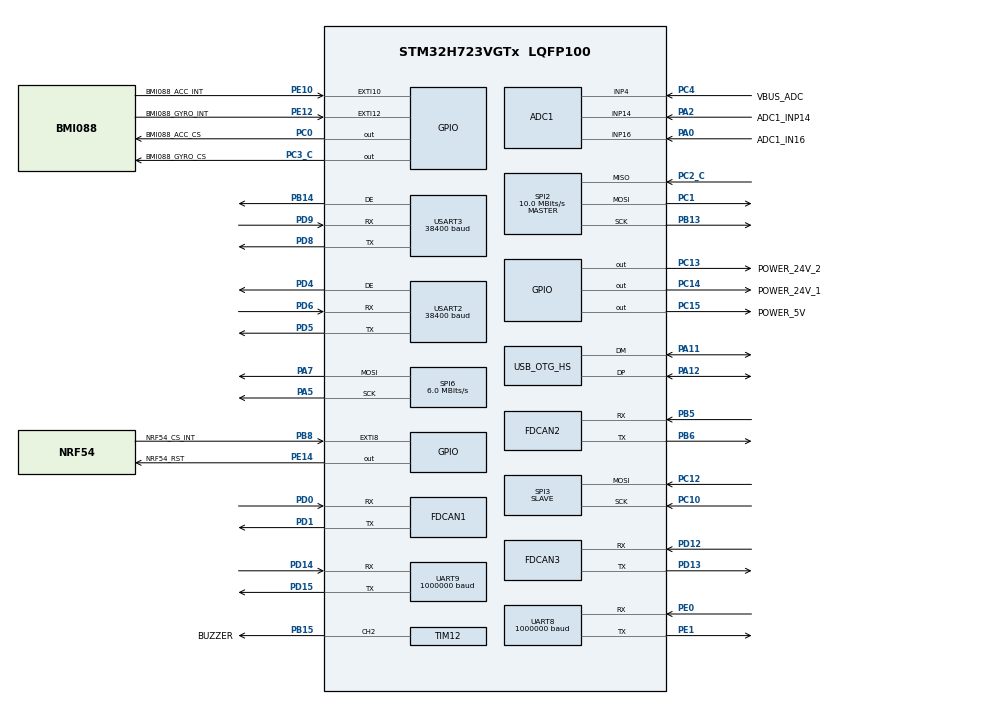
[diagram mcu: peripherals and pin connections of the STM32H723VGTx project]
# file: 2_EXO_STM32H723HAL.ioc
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ADC1.Channel-2\#ChannelRegularConversion=ADC_CHANNEL_4
ADC1.Channel-3\#ChannelRegularConversion=ADC_CHANNEL_14
ADC1.Channel-4\#ChannelRegularConversion=ADC_CHANNEL_16
ADC1.ClockPrescaler=ADC_CLOCK_ASYNC_DIV4
ADC1.ContinuousConvMode=DISABLE
ADC1.ConversionDataManagement=ADC_CONVERSIONDATA_DMA_CIRCULAR
ADC1.DiscontinuousConvMode=DISABLE
ADC1.EOCSelection=ADC_EOC_SEQ_CONV
ADC1.ExternalTrigConv=ADC_EXTERNALTRIG_T2_TRGO
ADC1.NbrOfConversion=3
ADC1.NbrOfConversionFlag=1
ADC1.OffsetNumber-2\#ChannelRegularConversion=ADC_OFFSET_NONE
ADC1.OffsetNumber-3\#ChannelRegularConversion=ADC_OFFSET_NONE
ADC1.OffsetNumber-4\#ChannelRegularConversion=ADC_OFFSET_NONE
ADC1.OffsetSignedSaturation-2\#ChannelRegularConversion=DISABLE
ADC1.OffsetSignedSaturation-3\#ChannelRegularConversion=DISABLE
ADC1.OffsetSignedSaturation-4\#ChannelRegularConversion=DISABLE
ADC1.Overrun=ADC_OVR_DATA_PRESERVED
ADC1.OversamplingMode=ENABLE
ADC1.Rank-2\#ChannelRegularConversion=1
ADC1.Rank-3\#ChannelRegularConversion=2
ADC1.Rank-4\#ChannelRegularConversion=3
ADC1.Ratio=15
ADC1.RightBitShift=ADC_RIGHTBITSHIFT_4
ADC1.SamplingTime-2\#ChannelRegularConversion=ADC_SAMPLETIME_32CYCLES_5
ADC1.SamplingTime-3\#ChannelRegularConversion=ADC_SAMPLETIME_32CYCLES_5
ADC1.SamplingTime-4\#ChannelRegularConversion=ADC_SAMPLETIME_32CYCLES_5
ADC1.master=1
Bdma.Request0=SPI6_TX
Bdma.RequestsNb=1
Bdma.SPI6_TX.0.Direction=DMA_MEMORY_TO_PERIPH
Bdma.SPI6_TX.0.EventEnable=DISABLE
Bdma.SPI6_TX.0.Instance=BDMA_Channel0
Bdma.SPI6_TX.0.MemDataAlignment=DMA_MDATAALIGN_BYTE
Bdma.SPI6_TX.0.MemInc=DMA_MINC_ENABLE
Bdma.SPI6_TX.0.Mode=DMA_NORMAL
Bdma.SPI6_TX.0.PeriphDataAlignment=DMA_PDATAALIGN_BYTE
Bdma.SPI6_TX.0.PeriphInc=DMA_PINC_DISABLE
Bdma.SPI6_TX.0.Polarity=HAL_DMAMUX_REQ_GEN_RISING
Bdma.SPI6_TX.0.Priority=DMA_PRIORITY_LOW
Bdma.SPI6_TX.0.RequestNumber=1
Bdma.SPI6_TX.0.SignalID=NONE
Bdma.SPI6_TX.0.SyncEnable=DISABLE
Bdma.SPI6_TX.0.SyncPolarity=HAL_DMAMUX_SYNC_NO_EVENT
Bdma.SPI6_TX.0.SyncRequestNumber=1
Bdma.SPI6_TX.0.SyncSignalID=NONE
CORTEX_M7.AccessPermission-Cortex_Memory_Protection_Unit_Region0_Settings=MPU_REGION_FULL_ACCESS
CORTEX_M7.AccessPermission-Cortex_Memory_Protection_Unit_Region1_Settings=MPU_REGION_FULL_ACCESS
CORTEX_M7.AccessPermission-Cortex_Memory_Protection_Unit_Region2_Settings=MPU_REGION_FULL_ACCESS
CORTEX_M7.BaseAddress-Cortex_Memory_Protection_Unit_Region0_Settings=0x24000000
CORTEX_M7.BaseAddress-Cortex_Memory_Protection_Unit_Region1_Settings=0x30000000
CORTEX_M7.BaseAddress-Cortex_Memory_Protection_Unit_Region2_Settings=0x38000000
CORTEX_M7.CPU_DCache=Enabled
CORTEX_M7.CPU_ICache=Enabled
CORTEX_M7.DisableExec-Cortex_Memory_Protection_Unit_Region1_Settings=MPU_INSTRUCTION_ACCESS_DISABLE
CORTEX_M7.DisableExec-Cortex_Memory_Protection_Unit_Region2_Settings=MPU_INSTRUCTION_ACCESS_DISABLE
CORTEX_M7.Enable-Cortex_Memory_Protection_Unit_Region0_Settings=MPU_REGION_ENABLE
CORTEX_M7.Enable-Cortex_Memory_Protection_Unit_Region1_Settings=MPU_REGION_ENABLE
CORTEX_M7.Enable-Cortex_Memory_Protection_Unit_Region2_Settings=MPU_REGION_ENABLE
CORTEX_M7.IsBufferable-Cortex_Memory_Protection_Unit_Region0_Settings=MPU_ACCESS_BUFFERABLE
CORTEX_M7.IsCacheable-Cortex_Memory_Protection_Unit_Region0_Settings=MPU_ACCESS_CACHEABLE
CORTEX_M7.MPU_Control=MPU_HFNMI_PRIVDEF
CORTEX_M7.Size-Cortex_Memory_Protection_Unit_Region0_Settings=MPU_REGION_SIZE_512KB
CORTEX_M7.Size-Cortex_Memory_Protection_Unit_Region1_Settings=MPU_REGION_SIZE_4KB
CORTEX_M7.Size-Cortex_Memory_Protection_Unit_Region2_Settings=MPU_REGION_SIZE_4KB
CORTEX_M7.TypeExtField-Cortex_Memory_Protection_Unit_Region0_Settings=MPU_TEX_LEVEL1
CORTEX_M7.TypeExtField-Cortex_Memory_Protection_Unit_Region1_Settings=MPU_TEX_LEVEL1
CORTEX_M7.TypeExtField-Cortex_Memory_Protection_Unit_Region2_Settings=MPU_TEX_LEVEL1
Dma.ADC1.0.Direction=DMA_PERIPH_TO_MEMORY
Dma.ADC1.0.EventEnable=DISABLE
Dma.ADC1.0.FIFOMode=DMA_FIFOMODE_DISABLE
Dma.ADC1.0.Instance=DMA1_Stream0
Dma.ADC1.0.MemDataAlignment=DMA_MDATAALIGN_WORD
Dma.ADC1.0.MemInc=DMA_MINC_ENABLE
Dma.ADC1.0.Mode=DMA_CIRCULAR
Dma.ADC1.0.PeriphDataAlignment=DMA_PDATAALIGN_WORD
Dma.ADC1.0.PeriphInc=DMA_PINC_DISABLE
Dma.ADC1.0.Polarity=HAL_DMAMUX_REQ_GEN_RISING
Dma.ADC1.0.Priority=DMA_PRIORITY_HIGH
Dma.ADC1.0.RequestNumber=1
Dma.ADC1.0.SignalID=NONE
Dma.ADC1.0.SyncEnable=DISABLE
Dma.ADC1.0.SyncPolarity=HAL_DMAMUX_SYNC_NO_EVENT
Dma.ADC1.0.SyncRequestNumber=1
Dma.ADC1.0.SyncSignalID=NONE
Dma.Request0=ADC1
Dma.Request1=UART8_RX
Dma.Request10=SPI3_RX
Dma.Request2=UART9_RX
Dma.Request3=UART9_TX
Dma.Request4=SPI2_RX
Dma.Request5=SPI2_TX
Dma.Request6=USART2_RX
Dma.Request7=USART2_TX
Dma.Request8=USART3_RX
Dma.Request9=USART3_TX
Dma.SPI2_RX.4.Direction=DMA_PERIPH_TO_MEMORY
Dma.SPI2_RX.4.EventEnable=DISABLE
Dma.SPI2_RX.4.FIFOMode=DMA_FIFOMODE_DISABLE
Dma.SPI2_RX.4.Instance=DMA1_Stream2
Dma.SPI2_RX.4.MemDataAlignment=DMA_MDATAALIGN_BYTE
Dma.SPI2_RX.4.MemInc=DMA_MINC_ENABLE
Dma.SPI2_RX.4.Mode=DMA_NORMAL
Dma.SPI2_RX.4.PeriphDataAlignment=DMA_PDATAALIGN_BYTE
Dma.SPI2_RX.4.PeriphInc=DMA_PINC_DISABLE
Dma.SPI2_RX.4.Polarity=HAL_DMAMUX_REQ_GEN_RISING
Dma.SPI2_RX.4.Priority=DMA_PRIORITY_HIGH
Dma.SPI2_RX.4.RequestNumber=1
Dma.SPI2_RX.4.SignalID=NONE
Dma.SPI2_RX.4.SyncEnable=DISABLE
Dma.SPI2_RX.4.SyncPolarity=HAL_DMAMUX_SYNC_NO_EVENT
Dma.SPI2_RX.4.SyncRequestNumber=1
Dma.SPI2_RX.4.SyncSignalID=NONE
Dma.SPI2_TX.5.Direction=DMA_MEMORY_TO_PERIPH
Dma.SPI2_TX.5.EventEnable=DISABLE
Dma.SPI2_TX.5.FIFOMode=DMA_FIFOMODE_DISABLE
Dma.SPI2_TX.5.Instance=DMA1_Stream3
Dma.SPI2_TX.5.MemDataAlignment=DMA_MDATAALIGN_BYTE
Dma.SPI2_TX.5.MemInc=DMA_MINC_ENABLE
Dma.SPI2_TX.5.Mode=DMA_NORMAL
Dma.SPI2_TX.5.PeriphDataAlignment=DMA_PDATAALIGN_BYTE
Dma.SPI2_TX.5.PeriphInc=DMA_PINC_DISABLE
Dma.SPI2_TX.5.Polarity=HAL_DMAMUX_REQ_GEN_RISING
Dma.SPI2_TX.5.Priority=DMA_PRIORITY_HIGH
Dma.SPI2_TX.5.RequestNumber=1
Dma.SPI2_TX.5.SignalID=NONE
Dma.SPI2_TX.5.SyncEnable=DISABLE
Dma.SPI2_TX.5.SyncPolarity=HAL_DMAMUX_SYNC_NO_EVENT
Dma.SPI2_TX.5.SyncRequestNumber=1
Dma.SPI2_TX.5.SyncSignalID=NONE
Dma.SPI3_RX.10.Direction=DMA_PERIPH_TO_MEMORY
Dma.SPI3_RX.10.EventEnable=DISABLE
Dma.SPI3_RX.10.FIFOMode=DMA_FIFOMODE_DISABLE
Dma.SPI3_RX.10.Instance=DMA2_Stream2
Dma.SPI3_RX.10.MemDataAlignment=DMA_MDATAALIGN_BYTE
Dma.SPI3_RX.10.MemInc=DMA_MINC_ENABLE
Dma.SPI3_RX.10.Mode=DMA_NORMAL
Dma.SPI3_RX.10.PeriphDataAlignment=DMA_PDATAALIGN_BYTE
Dma.SPI3_RX.10.PeriphInc=DMA_PINC_DISABLE
Dma.SPI3_RX.10.Polarity=HAL_DMAMUX_REQ_GEN_RISING
Dma.SPI3_RX.10.Priority=DMA_PRIORITY_VERY_HIGH
Dma.SPI3_RX.10.RequestNumber=1
Dma.SPI3_RX.10.SignalID=NONE
Dma.SPI3_RX.10.SyncEnable=DISABLE
Dma.SPI3_RX.10.SyncPolarity=HAL_DMAMUX_SYNC_NO_EVENT
Dma.SPI3_RX.10.SyncRequestNumber=1
Dma.SPI3_RX.10.SyncSignalID=NONE
Dma.UART8_RX.1.Direction=DMA_PERIPH_TO_MEMORY
Dma.UART8_RX.1.EventEnable=DISABLE
Dma.UART8_RX.1.FIFOMode=DMA_FIFOMODE_DISABLE
Dma.UART8_RX.1.Instance=DMA1_Stream1
Dma.UART8_RX.1.MemDataAlignment=DMA_MDATAALIGN_BYTE
Dma.UART8_RX.1.MemInc=DMA_MINC_ENABLE
Dma.UART8_RX.1.Mode=DMA_NORMAL
Dma.UART8_RX.1.PeriphDataAlignment=DMA_PDATAALIGN_BYTE
Dma.UART8_RX.1.PeriphInc=DMA_PINC_DISABLE
Dma.UART8_RX.1.Polarity=HAL_DMAMUX_REQ_GEN_RISING
Dma.UART8_RX.1.Priority=DMA_PRIORITY_VERY_HIGH
Dma.UART8_RX.1.RequestNumber=1
Dma.UART8_RX.1.SignalID=NONE
Dma.UART8_RX.1.SyncEnable=DISABLE
Dma.UART8_RX.1.SyncPolarity=HAL_DMAMUX_SYNC_NO_EVENT
Dma.UART8_RX.1.SyncRequestNumber=1
Dma.UART8_RX.1.SyncSignalID=NONE
Dma.UART9_RX.2.Direction=DMA_PERIPH_TO_MEMORY
Dma.UART9_RX.2.EventEnable=DISABLE
Dma.UART9_RX.2.FIFOMode=DMA_FIFOMODE_DISABLE
Dma.UART9_RX.2.Instance=DMA2_Stream0
Dma.UART9_RX.2.MemDataAlignment=DMA_MDATAALIGN_BYTE
Dma.UART9_RX.2.MemInc=DMA_MINC_ENABLE
Dma.UART9_RX.2.Mode=DMA_NORMAL
Dma.UART9_RX.2.PeriphDataAlignment=DMA_PDATAALIGN_BYTE
Dma.UART9_RX.2.PeriphInc=DMA_PINC_DISABLE
Dma.UART9_RX.2.Polarity=HAL_DMAMUX_REQ_GEN_RISING
Dma.UART9_RX.2.Priority=DMA_PRIORITY_LOW
Dma.UART9_RX.2.RequestNumber=1
Dma.UART9_RX.2.SignalID=NONE
Dma.UART9_RX.2.SyncEnable=DISABLE
Dma.UART9_RX.2.SyncPolarity=HAL_DMAMUX_SYNC_NO_EVENT
Dma.UART9_RX.2.SyncRequestNumber=1
Dma.UART9_RX.2.SyncSignalID=NONE
Dma.UART9_TX.3.Direction=DMA_MEMORY_TO_PERIPH
Dma.UART9_TX.3.EventEnable=DISABLE
Dma.UART9_TX.3.FIFOMode=DMA_FIFOMODE_DISABLE
Dma.UART9_TX.3.Instance=DMA2_Stream1
Dma.UART9_TX.3.MemDataAlignment=DMA_MDATAALIGN_BYTE
Dma.UART9_TX.3.MemInc=DMA_MINC_ENABLE
Dma.UART9_TX.3.Mode=DMA_NORMAL
Dma.UART9_TX.3.PeriphDataAlignment=DMA_PDATAALIGN_BYTE
Dma.UART9_TX.3.PeriphInc=DMA_PINC_DISABLE
Dma.UART9_TX.3.Polarity=HAL_DMAMUX_REQ_GEN_RISING
Dma.UART9_TX.3.Priority=DMA_PRIORITY_LOW
Dma.UART9_TX.3.RequestNumber=1
Dma.UART9_TX.3.SignalID=NONE
Dma.UART9_TX.3.SyncEnable=DISABLE
Dma.UART9_TX.3.SyncPolarity=HAL_DMAMUX_SYNC_NO_EVENT
Dma.UART9_TX.3.SyncRequestNumber=1
Dma.UART9_TX.3.SyncSignalID=NONE
Dma.USART2_RX.6.Direction=DMA_PERIPH_TO_MEMORY
Dma.USART2_RX.6.EventEnable=DISABLE
Dma.USART2_RX.6.FIFOMode=DMA_FIFOMODE_DISABLE
Dma.USART2_RX.6.Instance=DMA1_Stream4
Dma.USART2_RX.6.MemDataAlignment=DMA_MDATAALIGN_BYTE
Dma.USART2_RX.6.MemInc=DMA_MINC_ENABLE
Dma.USART2_RX.6.Mode=DMA_NORMAL
Dma.USART2_RX.6.PeriphDataAlignment=DMA_PDATAALIGN_BYTE
Dma.USART2_RX.6.PeriphInc=DMA_PINC_DISABLE
Dma.USART2_RX.6.Polarity=HAL_DMAMUX_REQ_GEN_RISING
Dma.USART2_RX.6.Priority=DMA_PRIORITY_HIGH
Dma.USART2_RX.6.RequestNumber=1
Dma.USART2_RX.6.SignalID=NONE
Dma.USART2_RX.6.SyncEnable=DISABLE
Dma.USART2_RX.6.SyncPolarity=HAL_DMAMUX_SYNC_NO_EVENT
Dma.USART2_RX.6.SyncRequestNumber=1
Dma.USART2_RX.6.SyncSignalID=NONE
Dma.USART2_TX.7.Direction=DMA_MEMORY_TO_PERIPH
Dma.USART2_TX.7.EventEnable=DISABLE
Dma.USART2_TX.7.FIFOMode=DMA_FIFOMODE_DISABLE
Dma.USART2_TX.7.Instance=DMA1_Stream5
Dma.USART2_TX.7.MemDataAlignment=DMA_MDATAALIGN_BYTE
Dma.USART2_TX.7.MemInc=DMA_MINC_ENABLE
Dma.USART2_TX.7.Mode=DMA_NORMAL
Dma.USART2_TX.7.PeriphDataAlignment=DMA_PDATAALIGN_BYTE
Dma.USART2_TX.7.PeriphInc=DMA_PINC_DISABLE
Dma.USART2_TX.7.Polarity=HAL_DMAMUX_REQ_GEN_RISING
Dma.USART2_TX.7.Priority=DMA_PRIORITY_HIGH
Dma.USART2_TX.7.RequestNumber=1
Dma.USART2_TX.7.SignalID=NONE
Dma.USART2_TX.7.SyncEnable=DISABLE
Dma.USART2_TX.7.SyncPolarity=HAL_DMAMUX_SYNC_NO_EVENT
Dma.USART2_TX.7.SyncRequestNumber=1
Dma.USART2_TX.7.SyncSignalID=NONE
Dma.USART3_RX.8.Direction=DMA_PERIPH_TO_MEMORY
Dma.USART3_RX.8.EventEnable=DISABLE
Dma.USART3_RX.8.FIFOMode=DMA_FIFOMODE_DISABLE
Dma.USART3_RX.8.Instance=DMA1_Stream6
Dma.USART3_RX.8.MemDataAlignment=DMA_MDATAALIGN_BYTE
Dma.USART3_RX.8.MemInc=DMA_MINC_ENABLE
Dma.USART3_RX.8.Mode=DMA_NORMAL
Dma.USART3_RX.8.PeriphDataAlignment=DMA_PDATAALIGN_BYTE
Dma.USART3_RX.8.PeriphInc=DMA_PINC_DISABLE
Dma.USART3_RX.8.Polarity=HAL_DMAMUX_REQ_GEN_RISING
Dma.USART3_RX.8.Priority=DMA_PRIORITY_HIGH
Dma.USART3_RX.8.RequestNumber=1
Dma.USART3_RX.8.SignalID=NONE
Dma.USART3_RX.8.SyncEnable=DISABLE
Dma.USART3_RX.8.SyncPolarity=HAL_DMAMUX_SYNC_NO_EVENT
Dma.USART3_RX.8.SyncRequestNumber=1
Dma.USART3_RX.8.SyncSignalID=NONE
Dma.USART3_TX.9.Direction=DMA_MEMORY_TO_PERIPH
Dma.USART3_TX.9.EventEnable=DISABLE
Dma.USART3_TX.9.FIFOMode=DMA_FIFOMODE_DISABLE
Dma.USART3_TX.9.Instance=DMA1_Stream7
Dma.USART3_TX.9.MemDataAlignment=DMA_MDATAALIGN_BYTE
Dma.USART3_TX.9.MemInc=DMA_MINC_ENABLE
Dma.USART3_TX.9.Mode=DMA_NORMAL
Dma.USART3_TX.9.PeriphDataAlignment=DMA_PDATAALIGN_BYTE
Dma.USART3_TX.9.PeriphInc=DMA_PINC_DISABLE
Dma.USART3_TX.9.Polarity=HAL_DMAMUX_REQ_GEN_RISING
Dma.USART3_TX.9.Priority=DMA_PRIORITY_HIGH
Dma.USART3_TX.9.RequestNumber=1
Dma.USART3_TX.9.SignalID=NONE
Dma.USART3_TX.9.SyncEnable=DISABLE
Dma.USART3_TX.9.SyncPolarity=HAL_DMAMUX_SYNC_NO_EVENT
Dma.USART3_TX.9.SyncRequestNumber=1
Dma.USART3_TX.9.SyncSignalID=NONE
FDCAN1.AutoRetransmission=ENABLE
FDCAN1.CalculateBaudRateNominal=1000000
FDCAN1.CalculateTimeBitNominal=1000
FDCAN1.CalculateTimeQuantumNominal=12.5
FDCAN1.DataSyncJumpWidth=2
FDCAN1.DataTimeSeg1=13
FDCAN1.DataTimeSeg2=2
FDCAN1.ExtFiltersNbr=4
FDCAN1.NominalPrescaler=1
FDCAN1.NominalSyncJumpWidth=20
FDCAN1.NominalTimeSeg1=59
FDCAN1.NominalTimeSeg2=20
FDCAN1.ProtocolException=ENABLE
FDCAN1.RxBuffersNbr=2
FDCAN1.RxFifo0ElmtsNbr=8
FDCAN1.RxFifo1ElmtsNbr=8
FDCAN1.StdFiltersNbr=4
FDCAN1.TxBuffersNbr=8
FDCAN1.TxEventsNbr=8
FDCAN1.TxFifoQueueElmtsNbr=8
FDCAN2.AutoRetransmission=ENABLE
FDCAN2.CalculateBaudRateNominal=1000000
FDCAN2.CalculateTimeBitNominal=1000
FDCAN2.CalculateTimeQuantumNominal=12.5
FDCAN2.DataSyncJumpWidth=2
FDCAN2.DataTimeSeg1=13
FDCAN2.DataTimeSeg2=2
FDCAN2.ExtFiltersNbr=4
FDCAN2.MessageRAMOffset=0x200
FDCAN2.NominalPrescaler=1
FDCAN2.NominalSyncJumpWidth=20
FDCAN2.NominalTimeSeg1=59
FDCAN2.NominalTimeSeg2=20
FDCAN2.ProtocolException=ENABLE
FDCAN2.RxBuffersNbr=2
FDCAN2.RxFifo0ElmtsNbr=8
FDCAN2.RxFifo1ElmtsNbr=8
FDCAN2.StdFiltersNbr=4
FDCAN2.TxBuffersNbr=8
FDCAN2.TxEventsNbr=8
FDCAN2.TxFifoQueueElmtsNbr=8
FDCAN3.AutoRetransmission=ENABLE
FDCAN3.CalculateBaudRateNominal=1000000
FDCAN3.CalculateTimeBitNominal=1000
FDCAN3.CalculateTimeQuantumNominal=12.5
FDCAN3.DataSyncJumpWidth=2
FDCAN3.DataTimeSeg1=13
FDCAN3.DataTimeSeg2=2
FDCAN3.ExtFiltersNbr=4
FDCAN3.MessageRAMOffset=0x400
FDCAN3.NominalPrescaler=1
FDCAN3.NominalSyncJumpWidth=20
FDCAN3.NominalTimeSeg1=59
FDCAN3.NominalTimeSeg2=20
FDCAN3.ProtocolException=ENABLE
FDCAN3.RxBuffersNbr=2
FDCAN3.RxFifo0ElmtsNbr=8
FDCAN3.RxFifo1ElmtsNbr=8
FDCAN3.StdFiltersNbr=4
FDCAN3.TxBuffersNbr=8
FDCAN3.TxEventsNbr=8
FDCAN3.TxFifoQueueElmtsNbr=8
Mcu.Family=STM32H7
Mcu.Name=STM32H723VGTx
Mcu.Package=LQFP100
NVIC.BDMA_Channel0_IRQn=true\:13\:0\:true\:false\:true\:false\:true\:true
NVIC.DMA1_Stream0_IRQn=true\:4\:0\:true\:false\:true\:false\:true\:true
NVIC.DMA1_Stream1_IRQn=true\:4\:0\:true\:false\:true\:false\:true\:true
NVIC.DMA1_Stream2_IRQn=true\:4\:0\:true\:false\:true\:false\:true\:true
NVIC.DMA1_Stream3_IRQn=true\:4\:0\:true\:false\:true\:false\:true\:true
NVIC.DMA1_Stream4_IRQn=true\:4\:0\:true\:false\:true\:false\:true\:true
NVIC.DMA1_Stream5_IRQn=true\:4\:0\:true\:false\:true\:false\:true\:true
NVIC.DMA1_Stream6_IRQn=true\:4\:0\:true\:false\:true\:false\:true\:true
NVIC.DMA1_Stream7_IRQn=true\:4\:0\:true\:false\:true\:false\:true\:true
NVIC.DMA2_Stream0_IRQn=true\:12\:0\:true\:false\:true\:false\:true\:true
NVIC.DMA2_Stream1_IRQn=true\:12\:0\:true\:false\:true\:false\:true\:true
NVIC.DMA2_Stream2_IRQn=true\:4\:0\:true\:false\:true\:false\:true\:true
NVIC.EXTI9_5_IRQn=true\:3\:0\:true\:false\:true\:true\:true\:true
NVIC.FDCAN1_IT0_IRQn=true\:4\:0\:true\:false\:true\:true\:true\:true
NVIC.FDCAN2_IT0_IRQn=true\:4\:0\:true\:false\:true\:true\:true\:true
NVIC.FDCAN3_IT0_IRQn=true\:4\:0\:true\:false\:true\:true\:true\:true
NVIC.OTG_HS_IRQn=true\:14\:0\:true\:false\:true\:true\:true\:true
NVIC.PriorityGroup=NVIC_PRIORITYGROUP_4
NVIC.SPI2_IRQn=true\:4\:0\:true\:false\:true\:false\:true\:true
NVIC.SPI3_IRQn=true\:4\:0\:true\:false\:true\:false\:true\:true
NVIC.SPI6_IRQn=true\:14\:0\:true\:false\:true\:false\:true\:true
NVIC.TIM2_IRQn=true\:3\:0\:true\:false\:true\:true\:true\:true
NVIC.UART8_IRQn=true\:4\:0\:true\:false\:true\:true\:true\:true
NVIC.UART9_IRQn=true\:12\:0\:true\:false\:true\:true\:true\:true
NVIC.USART2_IRQn=true\:4\:0\:true\:false\:true\:true\:true\:true
NVIC.USART3_IRQn=true\:4\:0\:true\:false\:true\:true\:true\:true
PA0.GPIO_Label=ADC1_IN16
PA0.Mode=IN16-Single-Ended
PA0.Signal=ADC1_INP16
PA11.Mode=Device_Only_FS
PA11.Signal=USB_OTG_HS_DM
PA12.Mode=Device_Only_FS
PA12.Signal=USB_OTG_HS_DP
PA13(JTMS/SWDIO).Mode=Serial_Wire
PA13(JTMS/SWDIO).Signal=DEBUG_JTMS-SWDIO
PA14(JTCK/SWCLK).Mode=Serial_Wire
PA14(JTCK/SWCLK).Signal=DEBUG_JTCK-SWCLK
PA2.GPIO_Label=ADC1_INP14
PA2.Signal=ADCx_INP14
PA5.GPIO_Speed=GPIO_SPEED_FREQ_VERY_HIGH
PA5.Mode=TX_Only_Simplex_Unidirect_Master
PA5.Signal=SPI6_SCK
PA7.GPIO_Speed=GPIO_SPEED_FREQ_VERY_HIGH
PA7.Mode=TX_Only_Simplex_Unidirect_Master
PA7.Signal=SPI6_MOSI
PB13.GPIO_Speed=GPIO_SPEED_FREQ_VERY_HIGH
PB13.Mode=Full_Duplex_Master
PB13.Signal=SPI2_SCK
PB14.Mode=Hardware Flow Control (RS485)
PB14.Signal=USART3_DE
PB15.GPIO_Label=BUZZER
PB15.Signal=S_TIM12_CH2
PB5.Mode=FDCAN_Activate
PB5.Signal=FDCAN2_RX
PB6.Mode=FDCAN_Activate
PB6.Signal=FDCAN2_TX
PB8.GPIO_Label=NRF54_CS_INT
PB8.GPIO_ModeDefaultEXTI=GPIO_MODE_IT_RISING_FALLING
PB8.GPIO_PuPd=GPIO_PULLUP
PB8.Signal=GPXTI8
PC0.GPIO_Label=BMI088_ACC_CS
PC0.GPIO_Speed=GPIO_SPEED_FREQ_VERY_HIGH
PC0.PinState=GPIO_PIN_SET
PC0.Signal=GPIO_Output
PC1.GPIO_Speed=GPIO_SPEED_FREQ_VERY_HIGH
PC1.Mode=Full_Duplex_Master
PC1.Signal=SPI2_MOSI
PC10.Mode=RX_Only_Simplex_Unidirect_Slave
PC10.Signal=SPI3_SCK
PC12.Mode=RX_Only_Simplex_Unidirect_Slave
PC12.Signal=SPI3_MOSI
PC13.GPIO_Label=POWER_24V_2
PC13.PinState=GPIO_PIN_RESET
PC13.Signal=GPIO_Output
PC14-OSC32_IN.GPIO_Label=POWER_24V_1
PC14-OSC32_IN.PinState=GPIO_PIN_RESET
PC14-OSC32_IN.Signal=GPIO_Output
PC15-OSC32_OUT.GPIO_Label=POWER_5V
PC15-OSC32_OUT.PinState=GPIO_PIN_SET
PC15-OSC32_OUT.Signal=GPIO_Output
PC2_C.GPIO_Speed=GPIO_SPEED_FREQ_VERY_HIGH
PC2_C.Mode=Full_Duplex_Master
PC2_C.Signal=SPI2_MISO
PC3_C.GPIO_Label=BMI088_GYRO_CS
PC3_C.GPIO_Speed=GPIO_SPEED_FREQ_VERY_HIGH
PC3_C.PinState=GPIO_PIN_SET
PC3_C.Signal=GPIO_Output
PC4.GPIO_Label=VBUS_ADC
PC4.Signal=ADCx_INP4
PD0.Mode=FDCAN_Activate
PD0.Signal=FDCAN1_RX
PD1.Mode=FDCAN_Activate
PD1.Signal=FDCAN1_TX
PD12.Mode=FDCAN_Activate
PD12.Signal=FDCAN3_RX
PD13.Mode=FDCAN_Activate
PD13.Signal=FDCAN3_TX
PD14.Mode=Asynchronous
PD14.Signal=UART9_RX
PD15.Mode=Asynchronous
PD15.Signal=UART9_TX
PD4.Mode=Hardware Flow Control (RS485)
PD4.Signal=USART2_DE
PD5.Mode=Asynchronous
PD5.Signal=USART2_TX
PD6.Mode=Asynchronous
PD6.Signal=USART2_RX
PD8.Mode=Asynchronous
PD8.Signal=USART3_TX
PD9.Mode=Asynchronous
PD9.Signal=USART3_RX
PE0.Mode=Asynchronous
PE0.Signal=UART8_RX
PE1.Mode=Asynchronous
PE1.Signal=UART8_TX
PE10.GPIO_Label=BMI088_ACC_INT
PE10.Signal=GPXTI10
PE12.GPIO_Label=BMI088_GYRO_INT
PE12.Signal=GPXTI12
PE14.GPIO_Label=NRF54_RST
PE14.PinState=GPIO_PIN_SET
PE14.Signal=GPIO_Output
PH0-OSC_IN.Mode=HSE-External-Oscillator
PH0-OSC_IN.Signal=RCC_OSC_IN
PH1-OSC_OUT.Mode=HSE-External-Oscillator
PH1-OSC_OUT.Signal=RCC_OSC_OUT
ProjectManager.HeapSize=0x200
ProjectManager.StackSize=0x400
ProjectManager.TargetToolchain=STM32CubeIDE
RCC.ADCFreq_Value=96000000
RCC.APB1Freq_Value=120000000
RCC.APB2Freq_Value=120000000
RCC.APB3Freq_Value=120000000
RCC.APB4Freq_Value=120000000
RCC.CortexFreq_Value=480000000
RCC.D1PPRE=RCC_APB3_DIV2
RCC.D2PPRE1=RCC_APB1_DIV2
RCC.D2PPRE2=RCC_APB2_DIV2
RCC.D3PPRE=RCC_APB4_DIV2
RCC.DIVM1=2
RCC.DIVM2=2
RCC.DIVN1=40
RCC.DIVN2=16
RCC.DIVP1=1
RCC.DIVQ1=6
RCC.HCLKFreq_Value=240000000
RCC.HPRE=RCC_HCLK_DIV2
RCC.HSE_VALUE=24000000
RCC.PLL1_VCO_SEL-AdvancedSettings=RCC_PLL1VCOMEDIUM
RCC.PLL2FRACN=0
RCC.PLL2_VCO_SEL-AdvancedSettings=RCC_PLL2VCOMEDIUM
RCC.PLL3_VCI_Range-AdvancedSettings=RCC_PLL3VCIRANGE_0
RCC.PLLFRACN=0
RCC.PLLSourceVirtual=RCC_PLLSOURCE_HSE
RCC.SPI6CLockSelection=RCC_SPI6CLKSOURCE_HSE
RCC.SYSCLKFreq_VALUE=480000000
RCC.SYSCLKSource=RCC_SYSCLKSOURCE_PLLCLK
RCC.USBCLockSelection=RCC_USBCLKSOURCE_HSI48
RCC.USBFreq_Value=48000000
SH.ADCx_INP14.0=ADC1_INP14,IN14-Single-Ended
SH.ADCx_INP4.0=ADC1_INP4,IN4-Single-Ended
SH.S_TIM12_CH2.0=TIM12_CH2,PWM Generation2 CH2
SPI2.BaudRatePrescaler=SPI_BAUDRATEPRESCALER_8
SPI2.CLKPhase=SPI_PHASE_2EDGE
SPI2.CLKPolarity=SPI_POLARITY_HIGH
SPI2.CalculateBaudRate=10.0 MBits/s
SPI2.DataSize=SPI_DATASIZE_8BIT
SPI2.Direction=SPI_DIRECTION_2LINES
SPI2.Mode=SPI_MODE_MASTER
SPI2.VirtualType=VM_MASTER
SPI3.DataSize=SPI_DATASIZE_8BIT
SPI3.Direction=SPI_DIRECTION_2LINES_RXONLY
SPI3.Mode=SPI_MODE_SLAVE
SPI3.VirtualType=VM_SLAVE
SPI6.BaudRatePrescaler=SPI_BAUDRATEPRESCALER_4
SPI6.CLKPhase=SPI_PHASE_2EDGE
SPI6.CLKPolarity=SPI_POLARITY_LOW
SPI6.CalculateBaudRate=6.0 MBits/s
SPI6.DataSize=SPI_DATASIZE_8BIT
SPI6.Direction=SPI_DIRECTION_2LINES_TXONLY
SPI6.Mode=SPI_MODE_MASTER
SPI6.VirtualType=VM_MASTER
TIM12.Channel-PWM\ Generation2\ CH2=TIM_CHANNEL_2
TIM12.Period=2000-1
TIM12.Prescaler=24-1
TIM12.Pulse-PWM\ Generation2\ CH2=1000
TIM2.AutoReloadPreload=TIM_AUTORELOAD_PRELOAD_ENABLE
TIM2.Period=10-1
TIM2.Prescaler=24000-1
TIM2.TIM_MasterOutputTrigger=TIM_TRGO_UPDATE
UART8.BaudRate=1000000
UART8.FIFOMode=FIFOMODE_ENABLE
UART8.OverSampling=UART_OVERSAMPLING_8
UART8.OverrunDisableParam=UART_ADVFEATURE_OVERRUN_ENABLE
UART8.RXFIFOThreshold=RXFIFO_THRESHOLD_1EIGHTHFULL
UART8.TXFIFOThreshold=TXFIFO_THRESHOLD_1EIGHTHFULL
UART9.BaudRate=1000000
UART9.FIFOMode=FIFOMODE_ENABLE
UART9.OverSampling=UART_OVERSAMPLING_8
UART9.OverrunDisableParam=UART_ADVFEATURE_OVERRUN_ENABLE
USART2.BaudRate=38400
USART2.VirtualMode-Asynchronous=VM_ASYNC
USART2.VirtualMode-Hardware\ Flow\ Control\ (RS485)=VM_ASYNC
USART3.BaudRate=38400
USART3.VirtualMode-Asynchronous=VM_ASYNC
USART3.VirtualMode-Hardware\ Flow\ Control\ (RS485)=VM_ASYNC
USB_DEVICE.CLASS_NAME_HS=CDC
USB_DEVICE.VirtualMode=Cdc
USB_DEVICE.VirtualModeHS=Cdc_HS
USB_OTG_HS.VirtualMode-Device_Only_FS=Device_Only_FS
VP_MEMORYMAP_VS_MEMORYMAP.Mode=CurAppReg
VP_TIM2_VS_ClockSourceINT.Mode=Internal
VP_USB_DEVICE_VS_USB_DEVICE_CDC_HS.Mode=CDC_HS
board=custom

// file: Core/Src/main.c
/* USER CODE BEGIN Header */
/**
  ******************************************************************************
  * @file           : main.c
  * @brief          : Main program body
  ******************************************************************************
  * @attention
  *
  * Copyright (c) 2025 STMicroelectronics.
  * All rights reserved.
  *
  * This software is licensed under terms that can be found in the LICENSE file
  * in the root directory of this software component.
  * If no LICENSE file comes with this software, it is provided AS-IS.
  *
  ******************************************************************************
  */
/* USER CODE END Header */
#include "main.h"
#include "adc.h"
#include "bdma.h"
#include "dma.h"
#include "fdcan.h"
#include "spi.h"
#include "tim.h"
#include "usart.h"
#include "usb_device.h"
#include "gpio.h"

/* USER CODE BEGIN PV */
volatile uint8_t g_timer2_flag = 0;
/* USER CODE END PV */

void SystemClock_Config(void);
static void MPU_Config(void);

int main(void)
{

  /* MPU Configuration--------------------------------------------------------*/
  MPU_Config();

  /* Enable the CPU Cache */

  /* Enable I-Cache---------------------------------------------------------*/
  SCB_EnableICache();

  /* Enable D-Cache---------------------------------------------------------*/
  SCB_EnableDCache();

  /* MCU Configuration--------------------------------------------------------*/

  /* Reset of all peripherals, Initializes the Flash interface and the Systick. */
  HAL_Init();

  /* Configure the system clock */
  SystemClock_Config();

  /* Initialize all configured peripherals */
  MX_GPIO_Init();
  MX_DMA_Init();
  MX_BDMA_Init();
  MX_ADC1_Init();
  MX_FDCAN1_Init();
  MX_TIM2_Init();
  MX_TIM12_Init();
  MX_SPI6_Init();
  MX_USB_DEVICE_Init();
  MX_UART8_Init();
  MX_UART9_Init();
  MX_SPI2_Init();
  MX_USART2_UART_Init();
  MX_USART3_UART_Init();
  MX_FDCAN3_Init();
  MX_SPI3_Init();
  MX_FDCAN2_Init();
  /* USER CODE BEGIN 2 */
    AltMainTask(NULL);
  /* USER CODE END 2 */

  /* Infinite loop */
  /* USER CODE BEGIN WHILE */
    //AltMainTask();
  while (1)
  {
    /* USER CODE END WHILE */

  }
}

void SystemClock_Config(void)
{
  RCC_OscInitTypeDef RCC_OscInitStruct = {0};
  RCC_ClkInitTypeDef RCC_ClkInitStruct = {0};

  /** Supply configuration update enable
  */
  HAL_PWREx_ConfigSupply(PWR_LDO_SUPPLY);

  /** Configure the main internal regulator output voltage
  */
  __HAL_PWR_VOLTAGESCALING_CONFIG(PWR_REGULATOR_VOLTAGE_SCALE0);

  while(!__HAL_PWR_GET_FLAG(PWR_FLAG_VOSRDY)) {}

  /** Initializes the RCC Oscillators according to the specified parameters
  * in the RCC_OscInitTypeDef structure.
  */
  RCC_OscInitStruct.OscillatorType = RCC_OSCILLATORTYPE_HSI48|RCC_OSCILLATORTYPE_HSE;
  RCC_OscInitStruct.HSEState = RCC_HSE_ON;
  RCC_OscInitStruct.HSI48State = RCC_HSI48_ON;
  RCC_OscInitStruct.PLL.PLLState = RCC_PLL_ON;
  RCC_OscInitStruct.PLL.PLLSource = RCC_PLLSOURCE_HSE;
  RCC_OscInitStruct.PLL.PLLM = 2;
  RCC_OscInitStruct.PLL.PLLN = 40;
  RCC_OscInitStruct.PLL.PLLP = 1;
  RCC_OscInitStruct.PLL.PLLQ = 6;
  RCC_OscInitStruct.PLL.PLLR = 2;
  RCC_OscInitStruct.PLL.PLLRGE = RCC_PLL1VCIRANGE_3;
  RCC_OscInitStruct.PLL.PLLVCOSEL = RCC_PLL1VCOWIDE;
  RCC_OscInitStruct.PLL.PLLFRACN = 0;
  if (HAL_RCC_OscConfig(&RCC_OscInitStruct) != HAL_OK)
  {
    Error_Handler();
  }

  /** Initializes the CPU, AHB and APB buses clocks
  */
  RCC_ClkInitStruct.ClockType = RCC_CLOCKTYPE_HCLK|RCC_CLOCKTYPE_SYSCLK
                              |RCC_CLOCKTYPE_PCLK1|RCC_CLOCKTYPE_PCLK2
                              |RCC_CLOCKTYPE_D3PCLK1|RCC_CLOCKTYPE_D1PCLK1;
  RCC_ClkInitStruct.SYSCLKSource = RCC_SYSCLKSOURCE_PLLCLK;
  RCC_ClkInitStruct.SYSCLKDivider = RCC_SYSCLK_DIV1;
  RCC_ClkInitStruct.AHBCLKDivider = RCC_HCLK_DIV2;
  RCC_ClkInitStruct.APB3CLKDivider = RCC_APB3_DIV2;
  RCC_ClkInitStruct.APB1CLKDivider = RCC_APB1_DIV2;
  RCC_ClkInitStruct.APB2CLKDivider = RCC_APB2_DIV2;
  RCC_ClkInitStruct.APB4CLKDivider = RCC_APB4_DIV2;

  if (HAL_RCC_ClockConfig(&RCC_ClkInitStruct, FLASH_LATENCY_3) != HAL_OK)
  {
    Error_Handler();
  }
}

/* USER CODE BEGIN 4 */
void HAL_TIM_PeriodElapsedCallback(TIM_HandleTypeDef *htim)
{
    if (htim->Instance == TIM2)
    {
        g_timer2_flag = 1;
    }
}

/* USER CODE END 4 */

 /* MPU Configuration */

void MPU_Config(void)
{
  MPU_Region_InitTypeDef MPU_InitStruct = {0};

  /* Disables the MPU */
  HAL_MPU_Disable();

  /** Initializes and configures the Region and the memory to be protected
  */
  MPU_InitStruct.Enable = MPU_REGION_ENABLE;
  MPU_InitStruct.Number = MPU_REGION_NUMBER0;
  MPU_InitStruct.BaseAddress = 0x24000000;
  MPU_InitStruct.Size = MPU_REGION_SIZE_512KB;
  MPU_InitStruct.SubRegionDisable = 0x0;
  MPU_InitStruct.TypeExtField = MPU_TEX_LEVEL1;
  MPU_InitStruct.AccessPermission = MPU_REGION_FULL_ACCESS;
  MPU_InitStruct.DisableExec = MPU_INSTRUCTION_ACCESS_ENABLE;
  MPU_InitStruct.IsShareable = MPU_ACCESS_NOT_SHAREABLE;
  MPU_InitStruct.IsCacheable = MPU_ACCESS_CACHEABLE;
  MPU_InitStruct.IsBufferable = MPU_ACCESS_BUFFERABLE;

  HAL_MPU_ConfigRegion(&MPU_InitStruct);

  /** Initializes and configures the Region and the memory to be protected
  */
  MPU_InitStruct.Number = MPU_REGION_NUMBER1;
  MPU_InitStruct.BaseAddress = 0x30000000;
  MPU_InitStruct.Size = MPU_REGION_SIZE_4KB;
  MPU_InitStruct.DisableExec = MPU_INSTRUCTION_ACCESS_DISABLE;
  MPU_InitStruct.IsCacheable = MPU_ACCESS_NOT_CACHEABLE;
  MPU_InitStruct.IsBufferable = MPU_ACCESS_NOT_BUFFERABLE;

  HAL_MPU_ConfigRegion(&MPU_InitStruct);

  /** Initializes and configures the Region and the memory to be protected
  */
  MPU_InitStruct.Number = MPU_REGION_NUMBER2;
  MPU_InitStruct.BaseAddress = 0x38000000;

  HAL_MPU_ConfigRegion(&MPU_InitStruct);
  /* Enables the MPU */
  HAL_MPU_Enable(MPU_HFNMI_PRIVDEF);

}

void Error_Handler(void)
{
  __disable_irq();
  while (1)
  {
  }
}
